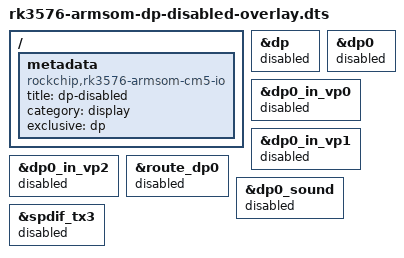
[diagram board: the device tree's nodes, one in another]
/dts-v1/;
/plugin/;

#include <dt-bindings/gpio/gpio.h>
#include <dt-bindings/pinctrl/rockchip.h>
#include <dt-bindings/display/drm_mipi_dsi.h>
#include <dt-bindings/interrupt-controller/irq.h>

/ {
    metadata {
        title = "dp-disabled";
        category = "display";
        compatible = "rockchip,rk3576-armsom-cm5-io", "rockchip,rk3588-armsom-sige5";
        exclusive = "dp";
    };

    fragment@0 {
        target = <&dp>;

        __overlay__ {
            status = "disabled";
        };
    };

    fragment@1 {
        target = <&dp0>;

        __overlay__ {
            status = "disabled";
        };
    };

    fragment@2 {
        target = <&dp0_in_vp0>;

        __overlay__ {
            status = "disabled";
        };
    };

    fragment@3 {
        target = <&dp0_in_vp1>;

        __overlay__ {
            status = "disabled";
        };
    };

    fragment@4 {
        target = <&dp0_in_vp2>;

        __overlay__ {
            status = "disabled";
        };
    };

    /* Leave shared VOP ports available to HDMI/DSI routes. */

    fragment@6 {
        target = <&route_dp0>;

        __overlay__ {
            status = "disabled";
        };
    };

    fragment@7 {
        target = <&dp0_sound>;

        __overlay__ {
            status = "disabled";
        };
    };

    fragment@8 {
        target = <&spdif_tx3>;

        __overlay__ {
            status = "disabled";
        };
    };
};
